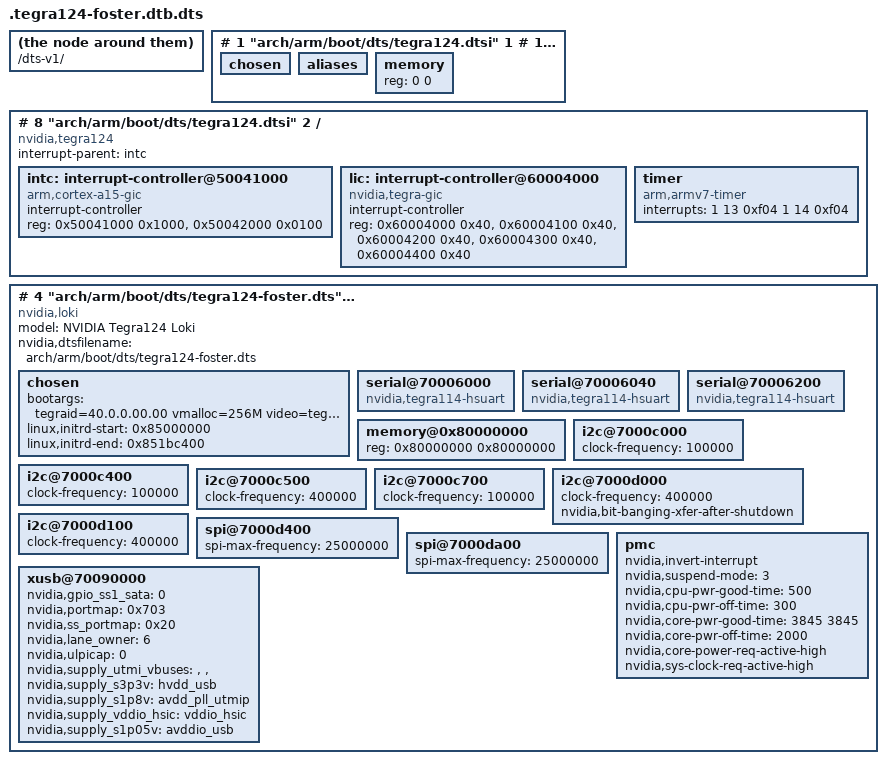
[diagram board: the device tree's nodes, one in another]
# 1 "arch/arm/boot/dts/tegra124-foster.dts"
# 1 "<built-in>"
# 1 "<command-line>"
# 1 "arch/arm/boot/dts/tegra124-foster.dts"
/dts-v1/;

# 1 "arch/arm/boot/dts/tegra124.dtsi" 1
# 1 "/usr/src/kernel/arch/arm/boot/dts/include/dt-bindings/gpio/tegra-gpio.h" 1
# 13 "/usr/src/kernel/arch/arm/boot/dts/include/dt-bindings/gpio/tegra-gpio.h"
# 1 "/usr/src/kernel/arch/arm/boot/dts/include/dt-bindings/gpio/gpio.h" 1
# 14 "/usr/src/kernel/arch/arm/boot/dts/include/dt-bindings/gpio/tegra-gpio.h" 2
# 2 "arch/arm/boot/dts/tegra124.dtsi" 2
# 1 "/usr/src/kernel/arch/arm/boot/dts/include/dt-bindings/input/input.h" 1
# 3 "arch/arm/boot/dts/tegra124.dtsi" 2
# 1 "/usr/src/kernel/arch/arm/boot/dts/include/dt-bindings/interrupt-controller/arm-gic.h" 1







# 1 "/usr/src/kernel/arch/arm/boot/dts/include/dt-bindings/interrupt-controller/irq.h" 1
# 9 "/usr/src/kernel/arch/arm/boot/dts/include/dt-bindings/interrupt-controller/arm-gic.h" 2
# 4 "arch/arm/boot/dts/tegra124.dtsi" 2

/include/ "tegra124-soc.dtsi"

# 1 "arch/arm/boot/dts/skeleton.dtsi" 1






/ {
 #address-cells = <1>;
 #size-cells = <1>;
 chosen { };
 aliases { };
 memory { device_type = "memory"; reg = <0 0>; };
};
# 8 "arch/arm/boot/dts/tegra124.dtsi" 2

/ {
 compatible = "nvidia,tegra124";
 interrupt-parent = <&intc>;
 #address-cells = <1>;
 #size-cells = <1>;

 intc: interrupt-controller@50041000 {
  compatible = "arm,cortex-a15-gic";
  interrupt-controller;
  #interrupt-cells = <3>;
  reg = <0x50041000 0x1000>,
        <0x50042000 0x0100>;
 };

 lic: interrupt-controller@60004000 {
  compatible = "nvidia,tegra-gic";
  interrupt-controller;
  reg = <0x60004000 0x40>,
        <0x60004100 0x40>,
        <0x60004200 0x40>,
        <0x60004300 0x40>,
        <0x60004400 0x40>;
        };

 timer {
  compatible = "arm,armv7-timer";
  interrupts = <1 13 0xf04
         1 14 0xf04>;
 };
};
# 4 "arch/arm/boot/dts/tegra124-foster.dts" 2


/ {
 model = "NVIDIA Tegra124 Loki";
 compatible = "nvidia,loki", "nvidia,tegra124";
 nvidia,dtsfilename = "arch/arm/boot/dts/tegra124-foster.dts";
 #address-cells = <1>;
 #size-cells = <1>;

 chosen {
  bootargs = "tegraid=40.0.0.00.00 vmalloc=256M video=tegrafb console=ttyS0,115200n8 earlyprintk";
  linux,initrd-start = <0x85000000>;
  linux,initrd-end = <0x851bc400>;
 };

 serial@70006000 {
  compatible = "nvidia,tegra114-hsuart";
  status = "okay";
 };

 serial@70006040 {
  compatible = "nvidia,tegra114-hsuart";
  status = "okay";
 };

 serial@70006200 {
  compatible = "nvidia,tegra114-hsuart";
  status = "okay";
 };

 memory@0x80000000 {
  device_type = "memory";
  reg = <0x80000000 0x80000000>;
 };

 i2c@7000c000 {
  status = "okay";
  clock-frequency = <100000>;
 };

 i2c@7000c400 {
  status = "okay";
  clock-frequency = <100000>;
 };

 i2c@7000c500 {
  status = "okay";
  clock-frequency = <400000>;
 };

 i2c@7000c700 {
  status = "okay";
  clock-frequency = <100000>;
 };

 i2c@7000d000 {
  status = "okay";
  clock-frequency = <400000>;
  nvidia,bit-banging-xfer-after-shutdown;
 };

 i2c@7000d100 {
  status = "okay";
  clock-frequency = <400000>;
 };

 spi@7000d400 {
  status = "okay";
  spi-max-frequency = <25000000>;
 };

 spi@7000da00 {
  status = "okay";
  spi-max-frequency = <25000000>;
 };

 pmc {
  status = "okay";
  nvidia,invert-interrupt;
  nvidia,suspend-mode = <3>;
  nvidia,cpu-pwr-good-time = <500>;
  nvidia,cpu-pwr-off-time = <300>;
  nvidia,core-pwr-good-time = <3845 3845>;
  nvidia,core-pwr-off-time = <2000>;
  nvidia,core-power-req-active-high;
  nvidia,sys-clock-req-active-high;
 };

 xusb@70090000 {


  nvidia,gpio_ss1_sata = <0>;
  nvidia,portmap = <0x703>;
  nvidia,ss_portmap = <0x20>;
  nvidia,lane_owner = <6>;
  nvidia,ulpicap = <0>;
  nvidia,supply_utmi_vbuses = "", "", "";
  nvidia,supply_s3p3v = "hvdd_usb";
  nvidia,supply_s1p8v = "avdd_pll_utmip";
  nvidia,supply_vddio_hsic = "vddio_hsic";
  nvidia,supply_s1p05v = "avddio_usb";
  status = "okay";
 };
};
